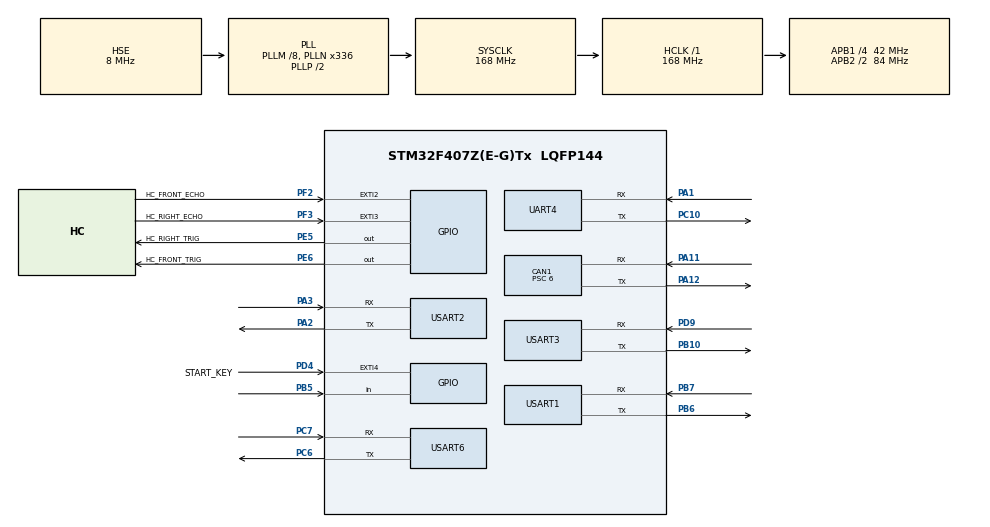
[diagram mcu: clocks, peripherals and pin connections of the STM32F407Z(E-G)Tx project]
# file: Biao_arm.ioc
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CAN1.ABOM=ENABLE
CAN1.BS1=CAN_BS1_11TQ
CAN1.BS2=CAN_BS2_2TQ
CAN1.CalculateBaudRate=500000
CAN1.CalculateTimeBit=2000
CAN1.CalculateTimeQuantum=142.85714285714286
CAN1.NART=ENABLE
CAN1.Prescaler=6
Dma.Request0=USART6_RX
Dma.USART6_RX.0.Direction=DMA_PERIPH_TO_MEMORY
Dma.USART6_RX.0.FIFOMode=DMA_FIFOMODE_DISABLE
Dma.USART6_RX.0.Instance=DMA2_Stream1
Dma.USART6_RX.0.MemDataAlignment=DMA_MDATAALIGN_BYTE
Dma.USART6_RX.0.MemInc=DMA_MINC_ENABLE
Dma.USART6_RX.0.Mode=DMA_CIRCULAR
Dma.USART6_RX.0.PeriphDataAlignment=DMA_PDATAALIGN_BYTE
Dma.USART6_RX.0.PeriphInc=DMA_PINC_DISABLE
Dma.USART6_RX.0.Priority=DMA_PRIORITY_MEDIUM
FREERTOS.Tasks01=main_task,8,1024,StartMainTask,Default,NULL,Dynamic,NULL,NULL;armEndLevelTask,40,1024,StartArmEndLevelTask,Default,NULL,Dynamic,NULL,NULL;chassisTask,32,1024,StartChassisTask,Default,NULL,Dynamic,NULL,NULL;ultrasonicTask,24,512,StartUltrasonicTask,Default,NULL,Dynamic,NULL,NULL
FREERTOS.configTOTAL_HEAP_SIZE=49152
Mcu.Family=STM32F4
Mcu.Name=STM32F407Z(E-G)Tx
Mcu.Package=LQFP144
NVIC.CAN1_RX0_IRQn=true\:5\:0\:true\:false\:true\:true\:true\:true\:true
NVIC.CAN1_SCE_IRQn=true\:5\:0\:true\:false\:true\:true\:true\:true\:true
NVIC.DMA2_Stream1_IRQn=true\:6\:0\:true\:false\:true\:true\:false\:true\:true
NVIC.EXTI3_IRQn=true\:6\:0\:true\:false\:true\:true\:true\:true\:true
NVIC.EXTI2_IRQn=true\:6\:0\:true\:false\:true\:true\:true\:true\:true
NVIC.EXTI4_IRQn=true\:6\:0\:true\:false\:true\:true\:true\:true\:true
NVIC.PriorityGroup=NVIC_PRIORITYGROUP_4
NVIC.TIM7_IRQn=true\:15\:0\:false\:false\:true\:false\:false\:true\:true
NVIC.TimeBase=TIM7_IRQn
NVIC.TimeBaseIP=TIM7
NVIC.UART4_IRQn=true\:5\:0\:false\:false\:true\:true\:true\:true\:true
NVIC.USART1_IRQn=true\:5\:0\:false\:false\:true\:true\:true\:true\:true
NVIC.USART2_IRQn=true\:5\:0\:false\:false\:true\:true\:true\:true\:true
NVIC.USART3_IRQn=true\:5\:0\:false\:false\:true\:true\:true\:true\:true
NVIC.USART6_IRQn=true\:6\:0\:true\:false\:true\:true\:true\:true\:true
PA1.Mode=Asynchronous
PA1.Signal=UART4_RX
PA11.Mode=CAN_Activate
PA11.Signal=CAN1_RX
PA12.Mode=CAN_Activate
PA12.Signal=CAN1_TX
PA13.Mode=Serial_Wire
PA13.Signal=SYS_JTMS-SWDIO
PA14.Mode=Serial_Wire
PA14.Signal=SYS_JTCK-SWCLK
PA2.Mode=Asynchronous
PA2.Signal=USART2_TX
PA3.Mode=Asynchronous
PA3.Signal=USART2_RX
PE5.GPIO_Label=HC_RIGHT_TRIG
PE5.Signal=GPIO_Output
PE6.GPIO_Label=HC_FRONT_TRIG
PE6.Signal=GPIO_Output
PF3.GPIO_ModeDefaultEXTI=GPIO_MODE_IT_RISING_FALLING
PF3.GPIO_Label=HC_RIGHT_ECHO
PF3.Signal=GPXTI3
PF2.GPIO_ModeDefaultEXTI=GPIO_MODE_IT_RISING_FALLING
PF2.GPIO_Label=HC_FRONT_ECHO
PF2.Signal=GPXTI2
PB10.Mode=Asynchronous
PB10.Signal=USART3_TX
PB5.Signal=GPIO_Input
PB6.Mode=Asynchronous
PB6.Signal=USART1_TX
PB7.Mode=Asynchronous
PB7.Signal=USART1_RX
PC10.Mode=Asynchronous
PC10.Signal=UART4_TX
PC14-OSC32_IN.Mode=LSE-External-Oscillator
PC14-OSC32_IN.Signal=RCC_OSC32_IN
PC15-OSC32_OUT.Mode=LSE-External-Oscillator
PC15-OSC32_OUT.Signal=RCC_OSC32_OUT
PC6.Mode=Asynchronous
PC6.Signal=USART6_TX
PC7.Mode=Asynchronous
PC7.Signal=USART6_RX
PD4.GPIO_ModeDefaultEXTI=GPIO_MODE_IT_RISING_FALLING
PD4.GPIO_Label=START_KEY
PD4.GPIO_PuPd=GPIO_PULLUP
PD4.Signal=GPXTI4
PD9.Mode=Asynchronous
PD9.Signal=USART3_RX
PH0-OSC_IN.Mode=HSE-External-Oscillator
PH0-OSC_IN.Signal=RCC_OSC_IN
PH1-OSC_OUT.Mode=HSE-External-Oscillator
PH1-OSC_OUT.Signal=RCC_OSC_OUT
ProjectManager.HeapSize=0x200
ProjectManager.StackSize=0x400
ProjectManager.TargetToolchain=MDK-ARM V5.32
RCC.48MHZClocksFreq_Value=84000000
RCC.AHBFreq_Value=168000000
RCC.APB1CLKDivider=RCC_HCLK_DIV4
RCC.APB1Freq_Value=42000000
RCC.APB1TimFreq_Value=84000000
RCC.APB2CLKDivider=RCC_HCLK_DIV2
RCC.APB2Freq_Value=84000000
RCC.APB2TimFreq_Value=168000000
RCC.CortexFreq_Value=168000000
RCC.HCLKFreq_Value=168000000
RCC.HSE_VALUE=8000000
RCC.HSI_VALUE=16000000
RCC.PLLM=8
RCC.PLLN=336
RCC.PLLSourceVirtual=RCC_PLLSOURCE_HSE
RCC.SYSCLKFreq_VALUE=168000000
RCC.SYSCLKSource=RCC_SYSCLKSOURCE_PLLCLK
RCC.VCOOutputFreq_Value=336000000
TIM2.ClockSource=TIM_CLOCKSOURCE_INTERNAL
TIM2.Period=4294967295
TIM2.Prescaler=83
UART4.VirtualMode=Asynchronous
USART1.VirtualMode=VM_ASYNC
USART2.VirtualMode=VM_ASYNC
USART3.VirtualMode=VM_ASYNC
USART6.VirtualMode=VM_ASYNC
VP_FREERTOS_VS_CMSIS_V2.Mode=CMSIS_V2
VP_TIM2_VS_ClockSourceINT.Mode=Internal
VP_SYS_VS_tim7.Mode=TIM7
board=custom

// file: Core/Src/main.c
/* USER CODE BEGIN Header */
/**
  ******************************************************************************
  * @file           : main.c
  * @brief          : Main program body
  ******************************************************************************
  * @attention
  *
  * Copyright (c) 2026 STMicroelectronics.
  * All rights reserved.
  *
  * This software is licensed under terms that can be found in the LICENSE file
  * in the root directory of this software component.
  * If no LICENSE file comes with this software, it is provided AS-IS.
  *
  ******************************************************************************
  */
/* USER CODE END Header */
#include "main.h"
#include "cmsis_os.h"
#include "can.h"
#include "dma.h"
#include "tim.h"
#include "usart.h"
#include "gpio.h"

/* USER CODE BEGIN Includes */
#include "main_task.h"
/* USER CODE END Includes */

void SystemClock_Config(void);
void MX_FREERTOS_Init(void);

int main(void)
{

  /* MCU Configuration--------------------------------------------------------*/

  /* Reset of all peripherals, Initializes the Flash interface and the Systick. */
  HAL_Init();

  /* Configure the system clock */
  SystemClock_Config();

  /* Initialize all configured peripherals */
  MX_GPIO_Init();
  MX_DMA_Init();
  MX_CAN1_Init();
  MX_USART6_UART_Init();
  MX_USART1_UART_Init();
  MX_USART3_UART_Init();
  MX_USART2_UART_Init();
  MX_UART4_Init();
  MX_TIM2_Init();

  /* Init scheduler */
  osKernelInitialize();  /* Call init function for freertos objects (in cmsis_os2.c) */
  MX_FREERTOS_Init();

  /* Start scheduler */
  osKernelStart();

  /* We should never get here as control is now taken by the scheduler */

  /* Infinite loop */
  while (1)
  {

  }
}

void SystemClock_Config(void)
{
  RCC_OscInitTypeDef RCC_OscInitStruct = {0};
  RCC_ClkInitTypeDef RCC_ClkInitStruct = {0};

  /** Configure the main internal regulator output voltage
  */
  __HAL_RCC_PWR_CLK_ENABLE();
  __HAL_PWR_VOLTAGESCALING_CONFIG(PWR_REGULATOR_VOLTAGE_SCALE1);

  /** Initializes the RCC Oscillators according to the specified parameters
  * in the RCC_OscInitTypeDef structure.
  */
  RCC_OscInitStruct.OscillatorType = RCC_OSCILLATORTYPE_HSE;
  RCC_OscInitStruct.HSEState = RCC_HSE_ON;
  RCC_OscInitStruct.PLL.PLLState = RCC_PLL_ON;
  RCC_OscInitStruct.PLL.PLLSource = RCC_PLLSOURCE_HSE;
  RCC_OscInitStruct.PLL.PLLM = 8;
  RCC_OscInitStruct.PLL.PLLN = 336;
  RCC_OscInitStruct.PLL.PLLP = RCC_PLLP_DIV2;
  RCC_OscInitStruct.PLL.PLLQ = 4;
  if (HAL_RCC_OscConfig(&RCC_OscInitStruct) != HAL_OK)
  {
    Error_Handler();
  }

  /** Initializes the CPU, AHB and APB buses clocks
  */
  RCC_ClkInitStruct.ClockType = RCC_CLOCKTYPE_HCLK|RCC_CLOCKTYPE_SYSCLK
                              |RCC_CLOCKTYPE_PCLK1|RCC_CLOCKTYPE_PCLK2;
  RCC_ClkInitStruct.SYSCLKSource = RCC_SYSCLKSOURCE_PLLCLK;
  RCC_ClkInitStruct.AHBCLKDivider = RCC_SYSCLK_DIV1;
  RCC_ClkInitStruct.APB1CLKDivider = RCC_HCLK_DIV4;
  RCC_ClkInitStruct.APB2CLKDivider = RCC_HCLK_DIV2;

  if (HAL_RCC_ClockConfig(&RCC_ClkInitStruct, FLASH_LATENCY_5) != HAL_OK)
  {
    Error_Handler();
  }
}

void HAL_TIM_PeriodElapsedCallback(TIM_HandleTypeDef *htim)
{
  if (htim->Instance == TIM7)
  {
    HAL_IncTick();
  }
  /* USER CODE BEGIN Callback 1 */
  if (htim->Instance == TIM7)
  {
    MainTask_StartButtonTick(HAL_GetTick());
  }
  /* USER CODE END Callback 1 */
}

void Error_Handler(void)
{
  __disable_irq();
  while (1)
  {
  }
}

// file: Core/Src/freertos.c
/* USER CODE BEGIN Header */
/**
  ******************************************************************************
  * File Name          : freertos.c
  * Description        : Code for freertos applications
  ******************************************************************************
  * @attention
  *
  * Copyright (c) 2026 STMicroelectronics.
  * All rights reserved.
  *
  * This software is licensed under terms that can be found in the LICENSE file
  * in the root directory of this software component.
  * If no LICENSE file comes with this software, it is provided AS-IS.
  *
  ******************************************************************************
  */
/* USER CODE END Header */

#include "FreeRTOS.h"
#include "task.h"
#include "main.h"
#include "cmsis_os.h"

/* USER CODE BEGIN Includes */
#include "main_task.h"
#include "arm_end_level_task.h"
#include "chassis_task.h"
#include "ultrasonic_task.h"
/* USER CODE END Includes */

/* Definitions for main_task */
osThreadId_t main_taskHandle;
const osThreadAttr_t main_task_attributes = {
  .name = "main_task",
  .stack_size = 1024 * 4,
  .priority = (osPriority_t) osPriorityLow,
};
/* Definitions for armEndLevelTask */
osThreadId_t armEndLevelTaskHandle;
const osThreadAttr_t armEndLevelTask_attributes = {
  .name = "armEndLevelTask",
  .stack_size = 1024 * 4,
  .priority = (osPriority_t) osPriorityHigh,
};
/* Definitions for chassisTask */
osThreadId_t chassisTaskHandle;
const osThreadAttr_t chassisTask_attributes = {
  .name = "chassisTask",
  .stack_size = 1024 * 4,
  .priority = (osPriority_t) osPriorityAboveNormal,
};
/* Definitions for ultrasonicTask */
osThreadId_t ultrasonicTaskHandle;
const osThreadAttr_t ultrasonicTask_attributes = {
  .name = "ultrasonicTask",
  .stack_size = 512 * 4,
  .priority = (osPriority_t) osPriorityNormal,
};

void StartMainTask(void *argument);
void StartArmEndLevelTask(void *argument);
void StartChassisTask(void *argument);
void StartUltrasonicTask(void *argument);

void MX_FREERTOS_Init(void); /* (MISRA C 2004 rule 8.1) */

void MX_FREERTOS_Init(void) {

  /* Create the thread(s) */
  /* creation of main_task */
  main_taskHandle = osThreadNew(StartMainTask, NULL, &main_task_attributes);

  /* creation of armEndLevelTask */
  armEndLevelTaskHandle = osThreadNew(StartArmEndLevelTask, NULL, &armEndLevelTask_attributes);

  /* creation of chassisTask */
  chassisTaskHandle = osThreadNew(StartChassisTask, NULL, &chassisTask_attributes);

  /* creation of ultrasonicTask */
  ultrasonicTaskHandle = osThreadNew(StartUltrasonicTask, NULL, &ultrasonicTask_attributes);

  /* USER CODE BEGIN RTOS_THREADS */
  if (main_taskHandle == NULL || armEndLevelTaskHandle == NULL || chassisTaskHandle == NULL || ultrasonicTaskHandle == NULL) Error_Handler();
  /* USER CODE END RTOS_THREADS */

}

/* USER CODE BEGIN Header_StartMainTask */
/*
  函数说明: 将 CubeMX 任务入口连接到业务任务。
  调用示例: 由 osThreadNew 自动启动。
  参数意义: argument 为任务参数，当前未使用。
*/
/* USER CODE END Header_StartMainTask */
void StartMainTask(void *argument)
{
  /* USER CODE BEGIN StartMainTask */
  MainTask_Run(argument);
  /* USER CODE END StartMainTask */
}

/* USER CODE BEGIN Header_StartArmEndLevelTask */
/*
  函数说明: 将 CubeMX 任务入口连接到业务任务。
  调用示例: 由 osThreadNew 自动启动。
  参数意义: argument 为任务参数，当前未使用。
*/
/* USER CODE END Header_StartArmEndLevelTask */
void StartArmEndLevelTask(void *argument)
{
  /* USER CODE BEGIN StartArmEndLevelTask */
  ArmEndLevelTask_Run(argument);
  /* USER CODE END StartArmEndLevelTask */
}

/* USER CODE BEGIN Header_StartChassisTask */
/*
  函数说明: 将 CubeMX 任务入口连接到业务任务。
  调用示例: 由 osThreadNew 自动启动。
  参数意义: argument 为任务参数，当前未使用。
*/
/* USER CODE END Header_StartChassisTask */
void StartChassisTask(void *argument)
{
  /* USER CODE BEGIN StartChassisTask */
  ChassisTask_Run(argument);
  /* USER CODE END StartChassisTask */
}

/* USER CODE BEGIN Header_StartUltrasonicTask */
/*
  函数说明: 将 CubeMX 任务入口连接到业务任务。
  调用示例: 由 osThreadNew 自动启动。
  参数意义: argument 为任务参数，当前未使用。
*/
/* USER CODE END Header_StartUltrasonicTask */
void StartUltrasonicTask(void *argument)
{
  /* USER CODE BEGIN StartUltrasonicTask */
  UltrasonicTask_Run(argument);
  /* USER CODE END StartUltrasonicTask */
}
